AUTOSAR XML (schema 4-2-2)
package /AUTOSAR_WdgM
  data type mapping set WdgM_Type_Map: mode-request-type-map{implementation-data-type=uint8, mode-group=WdgM_Mode}
  mode declaration group WdgM_Mode: category=EXPLICIT_ORDER, initial-mode=SUPERVISION_OK, on-transition-value=255
    5 x mode:
      SUPERVISION_OK: value=0
      SUPERVISION_FAILED: value=1
      SUPERVISION_EXPIRED: value=2
      SUPERVISION_STOPPED: value=3
      SUPERVISION_DEACTIVATED: value=4
  client server interface WdgM_AliveSupervision: is-service=true
    operation CheckpointReached: possible-error=E_NOT_OK
      arg CheckpointID: type=WdgM_CheckpointIdType, direction=IN
    error E_NOT_OK: error-code=1
  mode switch interface WdgM_IndividualMode: is-service=true
    mode group currentMode: type=WdgM_Mode
  mode switch interface WdgM_GlobalMode: is-service=true
    mode group currentMode: type=WdgM_Mode
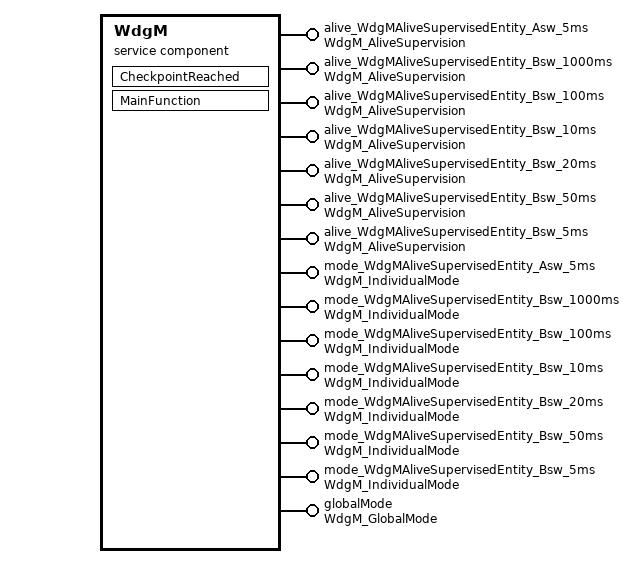
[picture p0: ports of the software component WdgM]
  service sw component type WdgM
    15 x provide port:
      alive_WdgMAliveSupervisedEntity_Asw_5ms: server-com-spec{operation=CheckpointReached, queue-length=2}, provided-interface=WdgM_AliveSupervision
      alive_WdgMAliveSupervisedEntity_Bsw_1000ms: server-com-spec{operation=CheckpointReached, queue-length=2}, provided-interface=WdgM_AliveSupervision
      alive_WdgMAliveSupervisedEntity_Bsw_100ms: server-com-spec{operation=CheckpointReached, queue-length=2}, provided-interface=WdgM_AliveSupervision
      alive_WdgMAliveSupervisedEntity_Bsw_10ms: server-com-spec{operation=CheckpointReached, queue-length=2}, provided-interface=WdgM_AliveSupervision
      alive_WdgMAliveSupervisedEntity_Bsw_20ms: server-com-spec{operation=CheckpointReached, queue-length=2}, provided-interface=WdgM_AliveSupervision
      alive_WdgMAliveSupervisedEntity_Bsw_50ms: server-com-spec{operation=CheckpointReached, queue-length=2}, provided-interface=WdgM_AliveSupervision
      alive_WdgMAliveSupervisedEntity_Bsw_5ms: server-com-spec{operation=CheckpointReached, queue-length=2}, provided-interface=WdgM_AliveSupervision
      mode_WdgMAliveSupervisedEntity_Asw_5ms: mode-switch-sender-com-spec{mode-group=currentMode, mode-switched-ack=timeout=1.0, queue-length=1}, provided-interface=WdgM_IndividualMode
      mode_WdgMAliveSupervisedEntity_Bsw_1000ms: mode-switch-sender-com-spec{mode-group=currentMode, mode-switched-ack=timeout=1.0, queue-length=1}, provided-interface=WdgM_IndividualMode
      mode_WdgMAliveSupervisedEntity_Bsw_100ms: mode-switch-sender-com-spec{mode-group=currentMode, mode-switched-ack=timeout=1.0, queue-length=1}, provided-interface=WdgM_IndividualMode
      mode_WdgMAliveSupervisedEntity_Bsw_10ms: mode-switch-sender-com-spec{mode-group=currentMode, mode-switched-ack=timeout=1.0, queue-length=1}, provided-interface=WdgM_IndividualMode
      mode_WdgMAliveSupervisedEntity_Bsw_20ms: mode-switch-sender-com-spec{mode-group=currentMode, mode-switched-ack=timeout=1.0, queue-length=1}, provided-interface=WdgM_IndividualMode
      mode_WdgMAliveSupervisedEntity_Bsw_50ms: mode-switch-sender-com-spec{mode-group=currentMode, mode-switched-ack=timeout=1.0, queue-length=1}, provided-interface=WdgM_IndividualMode
      mode_WdgMAliveSupervisedEntity_Bsw_5ms: mode-switch-sender-com-spec{mode-group=currentMode, mode-switched-ack=timeout=1.0, queue-length=1}, provided-interface=WdgM_IndividualMode
      globalMode: mode-switch-sender-com-spec{mode-group=currentMode, mode-switched-ack=timeout=1.0, queue-length=1}, provided-interface=WdgM_GlobalMode
    behavior WdgM_InternalBehaviour: data-type-mapping=WdgM_Type_Map
      7 x operation invoked event, all with start-on-event=CheckpointReached:
        OIE_CheckpointReached_WdgMAliveSupervisedEntity_Asw_5ms: operation=alive_WdgMAliveSupervisedEntity_Asw_5ms.CheckpointReached
        OIE_CheckpointReached_WdgMAliveSupervisedEntity_Bsw_1000ms: operation=alive_WdgMAliveSupervisedEntity_Bsw_1000ms.CheckpointReached
        OIE_CheckpointReached_WdgMAliveSupervisedEntity_Bsw_100ms: operation=alive_WdgMAliveSupervisedEntity_Bsw_100ms.CheckpointReached
        OIE_CheckpointReached_WdgMAliveSupervisedEntity_Bsw_10ms: operation=alive_WdgMAliveSupervisedEntity_Bsw_10ms.CheckpointReached
        OIE_CheckpointReached_WdgMAliveSupervisedEntity_Bsw_20ms: operation=alive_WdgMAliveSupervisedEntity_Bsw_20ms.CheckpointReached
        OIE_CheckpointReached_WdgMAliveSupervisedEntity_Bsw_50ms: operation=alive_WdgMAliveSupervisedEntity_Bsw_50ms.CheckpointReached
        OIE_CheckpointReached_WdgMAliveSupervisedEntity_Bsw_5ms: operation=alive_WdgMAliveSupervisedEntity_Bsw_5ms.CheckpointReached
      port-api-options:
        {enable-take-address=false, indirect-api=false, port-defined-argument-value{value=0, value-type=WdgM_SupervisedEntityIdType}, port=alive_WdgMAliveSupervisedEntity_Asw_5ms}
        indirect-api=true, port=mode_WdgMAliveSupervisedEntity_Asw_5ms
        {enable-take-address=false, indirect-api=false, port-defined-argument-value{value=1, value-type=WdgM_SupervisedEntityIdType}, port=alive_WdgMAliveSupervisedEntity_Bsw_1000ms}
        indirect-api=true, port=mode_WdgMAliveSupervisedEntity_Bsw_1000ms
        {enable-take-address=false, indirect-api=false, port-defined-argument-value{value=2, value-type=WdgM_SupervisedEntityIdType}, port=alive_WdgMAliveSupervisedEntity_Bsw_100ms}
        indirect-api=true, port=mode_WdgMAliveSupervisedEntity_Bsw_100ms
        {enable-take-address=false, indirect-api=false, port-defined-argument-value{value=3, value-type=WdgM_SupervisedEntityIdType}, port=alive_WdgMAliveSupervisedEntity_Bsw_10ms}
        indirect-api=true, port=mode_WdgMAliveSupervisedEntity_Bsw_10ms
        {enable-take-address=false, indirect-api=false, port-defined-argument-value{value=4, value-type=WdgM_SupervisedEntityIdType}, port=alive_WdgMAliveSupervisedEntity_Bsw_20ms}
        indirect-api=true, port=mode_WdgMAliveSupervisedEntity_Bsw_20ms
        {enable-take-address=false, indirect-api=false, port-defined-argument-value{value=5, value-type=WdgM_SupervisedEntityIdType}, port=alive_WdgMAliveSupervisedEntity_Bsw_50ms}
        indirect-api=true, port=mode_WdgMAliveSupervisedEntity_Bsw_50ms
        {enable-take-address=false, indirect-api=false, port-defined-argument-value{value=6, value-type=WdgM_SupervisedEntityIdType}, port=alive_WdgMAliveSupervisedEntity_Bsw_5ms}
        indirect-api=true, port=mode_WdgMAliveSupervisedEntity_Bsw_5ms
        enable-take-address=true, indirect-api=false, port=globalMode
      runnable CheckpointReached: can-be-invoked-concurrently=true, symbol=WdgM_CheckpointReached
      runnable MainFunction: symbol=WdgM_MainFunction
        8 x mode switch point:
          msp_WdgM_IndividualMode_WdgMAliveSupervisedEntity_Asw_5ms: mode-group=mode_WdgMAliveSupervisedEntity_Asw_5ms.currentMode
          msp_WdgM_IndividualMode_WdgMAliveSupervisedEntity_Bsw_1000ms: mode-group=mode_WdgMAliveSupervisedEntity_Bsw_1000ms.currentMode
          msp_WdgM_IndividualMode_WdgMAliveSupervisedEntity_Bsw_100ms: mode-group=mode_WdgMAliveSupervisedEntity_Bsw_100ms.currentMode
          msp_WdgM_IndividualMode_WdgMAliveSupervisedEntity_Bsw_10ms: mode-group=mode_WdgMAliveSupervisedEntity_Bsw_10ms.currentMode
          msp_WdgM_IndividualMode_WdgMAliveSupervisedEntity_Bsw_20ms: mode-group=mode_WdgMAliveSupervisedEntity_Bsw_20ms.currentMode
          msp_WdgM_IndividualMode_WdgMAliveSupervisedEntity_Bsw_50ms: mode-group=mode_WdgMAliveSupervisedEntity_Bsw_50ms.currentMode
          msp_WdgM_IndividualMode_WdgMAliveSupervisedEntity_Bsw_5ms: mode-group=mode_WdgMAliveSupervisedEntity_Bsw_5ms.currentMode
          msp_WdgM_GlobalMode: mode-group=globalMode.currentMode
